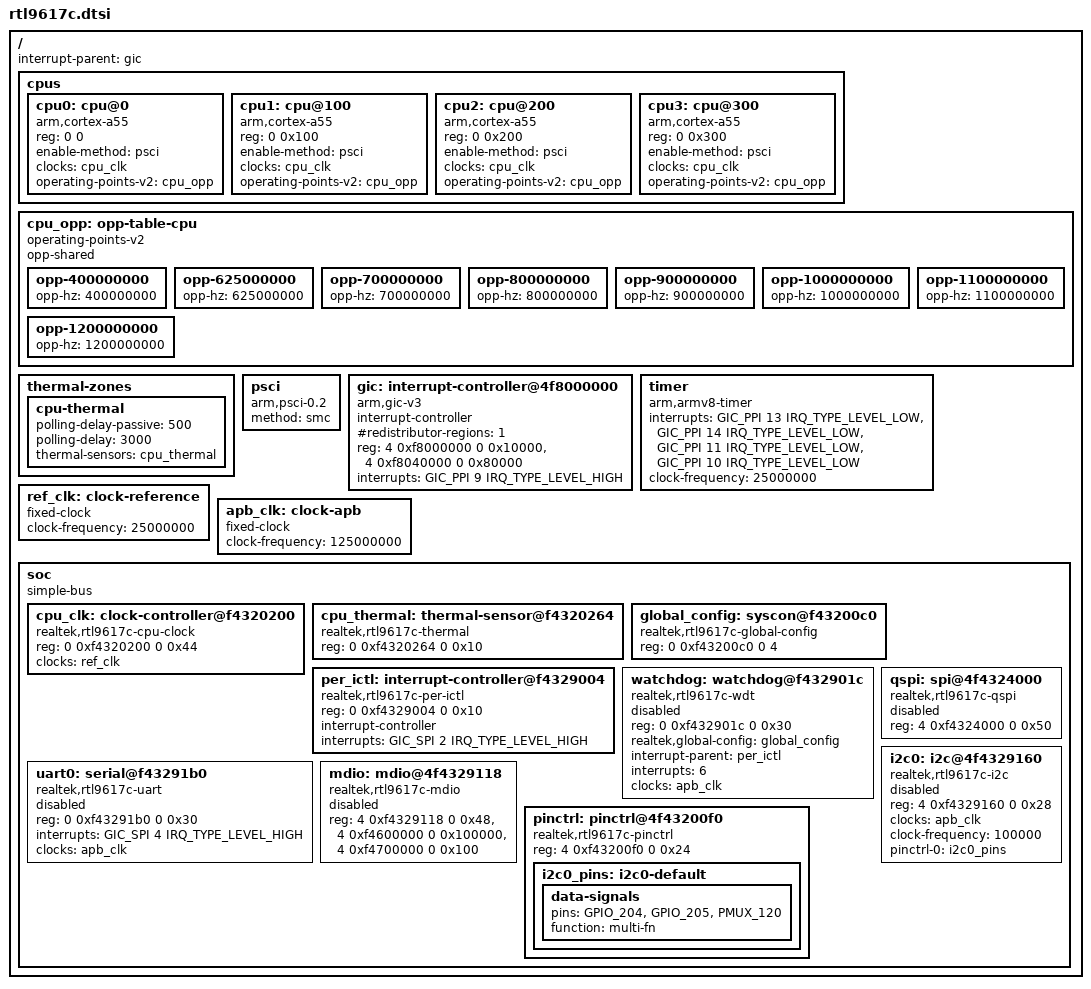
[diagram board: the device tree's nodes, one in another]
// SPDX-License-Identifier: GPL-2.0-only
// Register ranges, MPIDRs and reservations verified against TYFZA1's stock DTB:
// 5124f860df3bcd2e20b87d058e19b1ddfdc7a46c9d876663ba9feeff5a0f13ac.
#include <dt-bindings/interrupt-controller/arm-gic.h>

/ {
	#address-cells = <2>;
	#size-cells = <2>;
	interrupt-parent = <&gic>;

	cpus {
		#address-cells = <2>;
		#size-cells = <0>;
		cpu0: cpu@0 {
			device_type = "cpu";
			compatible = "arm,cortex-a55";
			reg = <0 0>;
			enable-method = "psci";
			clocks = <&cpu_clk>;
			clock-names = "cpu";
			operating-points-v2 = <&cpu_opp>;
		};
		cpu1: cpu@100 {
			device_type = "cpu";
			compatible = "arm,cortex-a55";
			reg = <0 0x100>;
			enable-method = "psci";
			clocks = <&cpu_clk>;
			clock-names = "cpu";
			operating-points-v2 = <&cpu_opp>;
		};
		cpu2: cpu@200 {
			device_type = "cpu";
			compatible = "arm,cortex-a55";
			reg = <0 0x200>;
			enable-method = "psci";
			clocks = <&cpu_clk>;
			clock-names = "cpu";
			operating-points-v2 = <&cpu_opp>;
		};
		cpu3: cpu@300 {
			device_type = "cpu";
			compatible = "arm,cortex-a55";
			reg = <0 0x300>;
			enable-method = "psci";
			clocks = <&cpu_clk>;
			clock-names = "cpu";
			operating-points-v2 = <&cpu_opp>;
		};
	};

	cpu_opp: opp-table-cpu {
		compatible = "operating-points-v2";
		opp-shared;
		opp-400000000 {
			opp-hz = /bits/ 64 <400000000>;
		};
		opp-625000000 {
			opp-hz = /bits/ 64 <625000000>;
		};
		opp-700000000 {
			opp-hz = /bits/ 64 <700000000>;
		};
		opp-800000000 {
			opp-hz = /bits/ 64 <800000000>;
		};
		opp-900000000 {
			opp-hz = /bits/ 64 <900000000>;
		};
		opp-1000000000 {
			opp-hz = /bits/ 64 <1000000000>;
		};
		opp-1100000000 {
			opp-hz = /bits/ 64 <1100000000>;
		};
		opp-1200000000 {
			opp-hz = /bits/ 64 <1200000000>;
		};
	};

	thermal-zones {
		cpu-thermal {
			polling-delay-passive = <500>;
			polling-delay = <3000>;
			thermal-sensors = <&cpu_thermal>;
		};
	};

	psci {
		compatible = "arm,psci-0.2";
		method = "smc";
	};

	gic: interrupt-controller@4f8000000 {
		compatible = "arm,gic-v3";
		#interrupt-cells = <3>;
		#address-cells = <2>;
		#size-cells = <2>;
		ranges;
		interrupt-controller;
		#redistributor-regions = <1>;
		reg = <4 0xf8000000 0 0x10000>,
		      <4 0xf8040000 0 0x80000>;
		interrupts = <GIC_PPI 9 IRQ_TYPE_LEVEL_HIGH>;
	};

	timer {
		compatible = "arm,armv8-timer";
		interrupts = <GIC_PPI 13 IRQ_TYPE_LEVEL_LOW>,
			     <GIC_PPI 14 IRQ_TYPE_LEVEL_LOW>,
			     <GIC_PPI 11 IRQ_TYPE_LEVEL_LOW>,
			     <GIC_PPI 10 IRQ_TYPE_LEVEL_LOW>;
		clock-frequency = <25000000>;
	};

	ref_clk: clock-reference {
		compatible = "fixed-clock";
		#clock-cells = <0>;
		clock-frequency = <25000000>;
	};

	apb_clk: clock-apb {
		compatible = "fixed-clock";
		#clock-cells = <0>;
		clock-frequency = <125000000>;
	};

	soc {
		compatible = "simple-bus";
		#address-cells = <2>;
		#size-cells = <2>;
		ranges;

		cpu_clk: clock-controller@f4320200 {
			compatible = "realtek,rtl9617c-cpu-clock";
			reg = <0 0xf4320200 0 0x44>;
			#clock-cells = <0>;
			clocks = <&ref_clk>;
		};

		cpu_thermal: thermal-sensor@f4320264 {
			compatible = "realtek,rtl9617c-thermal";
			reg = <0 0xf4320264 0 0x10>;
			#thermal-sensor-cells = <0>;
		};

		global_config: syscon@f43200c0 {
			compatible = "realtek,rtl9617c-global-config", "syscon";
			reg = <0 0xf43200c0 0 4>;
		};

		per_ictl: interrupt-controller@f4329004 {
			compatible = "realtek,rtl9617c-per-ictl", "cortina,per-ictl";
			reg = <0 0xf4329004 0 0x10>;
			interrupt-controller;
			#interrupt-cells = <1>;
			#address-cells = <0>;
			interrupts = <GIC_SPI 2 IRQ_TYPE_LEVEL_HIGH>;
		};

		watchdog: watchdog@f432901c {
			compatible = "realtek,rtl9617c-wdt", "cortina,wdt";
			reg = <0 0xf432901c 0 0x30>;
			realtek,global-config = <&global_config>;
			interrupt-parent = <&per_ictl>;
			interrupts = <6>;
			clocks = <&apb_clk>;
			status = "disabled";
		};

		uart0: serial@f43291b0 {
			compatible = "realtek,rtl9617c-uart", "cortina,serial";
			reg = <0 0xf43291b0 0 0x30>;
			interrupts = <GIC_SPI 4 IRQ_TYPE_LEVEL_HIGH>;
			clocks = <&apb_clk>;
			status = "disabled";
		};

		mdio: mdio@4f4329118 {
			compatible = "realtek,rtl9617c-mdio";
			// MDIO, PHY OCP and wrapper windows from the stock NI reg list.
			reg = <4 0xf4329118 0 0x48>,
			      <4 0xf4600000 0 0x100000>,
			      <4 0xf4700000 0 0x100>;
			reg-names = "mdio", "gphy-ocp", "gphy-wrap";
			#address-cells = <1>;
			#size-cells = <0>;
			status = "disabled";
		};

		qspi: spi@4f4324000 {
			compatible = "realtek,rtl9617c-qspi";
			reg = <4 0xf4324000 0 0x50>;
			#address-cells = <1>;
			#size-cells = <0>;
			status = "disabled";
		};

		pinctrl: pinctrl@4f43200f0 {
			compatible = "realtek,rtl9617c-pinctrl";
			reg = <4 0xf43200f0 0 0x24>;

			i2c0_pins: i2c0-default {
				data-signals {
					pins = "GPIO_204", "GPIO_205", "PMUX_120";
					function = "multi-fn";
				};
			};
		};

		i2c0: i2c@4f4329160 {
			compatible = "realtek,rtl9617c-i2c";
			reg = <4 0xf4329160 0 0x28>;
			clocks = <&apb_clk>;
			clock-frequency = <100000>;
			pinctrl-names = "default";
			pinctrl-0 = <&i2c0_pins>;
			#address-cells = <1>;
			#size-cells = <0>;
			status = "disabled";
		};
	};
};
